AUTOSAR XML (schema 4-0-3)
standard types defined: Boolean, UInt32, UInt8
package /AUTOSAR_Platform/DataConstrs
  range DC_Boolean: raw 0..1
  range DC_UInt8: raw 0..255
package /PATAC/MSM/ComponentTypes
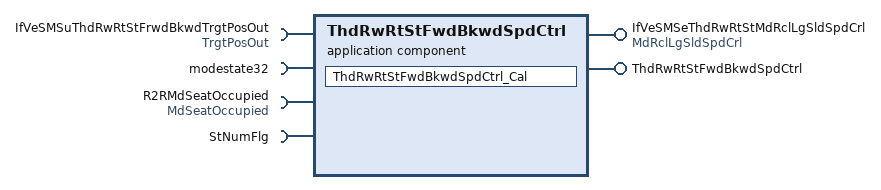
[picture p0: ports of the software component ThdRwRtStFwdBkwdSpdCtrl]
  application sw component type ThdRwRtStFwdBkwdSpdCtrl
    provide port IfVeSMSeThdRwRtStMdRclLgSldSpdCrl: nonqueued-sender-com-spec{data-element=MdRclLgSldSpdCrl/Val, init-value=0}, provided-interface=MdRclLgSldSpdCrl
    provide port ThdRwRtStFwdBkwdSpdCtrl: server-com-spec{operation=Cal, queue-length=1}, provided-interface=ThdRwRtStFwdBkwdSpdCtrl
    4 x require port:
      IfVeSMSuThdRwRtStFrwdBkwdTrgtPosOut: nonqueued-receiver-com-spec{data-element=TrgtPosOut/Val, filter=data-filter-type=ALWAYS, init-value=0}, required-interface=TrgtPosOut
      modestate32: nonqueued-receiver-com-spec{data-element=modestate32/Val, filter=data-filter-type=ALWAYS, init-value=0}, required-interface=modestate32
      R2RMdSeatOccupied: nonqueued-receiver-com-spec{data-element=MdSeatOccupied/Val, filter=data-filter-type=ALWAYS, init-value=0}, required-interface=MdSeatOccupied
      StNumFlg: required-interface=StNumFlg
        required-com-specs:
          data-element=Is4s, filter=data-filter-type=ALWAYS, init-value=0
          data-element=Is6s, filter=data-filter-type=ALWAYS, init-value=0
          data-element=Is6s7s, filter=data-filter-type=ALWAYS, init-value=0
          data-element=Is7s, filter=data-filter-type=ALWAYS, init-value=0
    behavior ThdRwRtStFwdBkwdSpdCtrl_InternalBehavior
      operation invoked event OIT_ThdRwRtStFwdBkwdSpdCtrl_Cal_ThdRwRtStFwdBkwdSpdCtrl_Cal: start-on-event=ThdRwRtStFwdBkwdSpdCtrl_Cal, operation=ThdRwRtStFwdBkwdSpdCtrl.Cal
      runnable ThdRwRtStFwdBkwdSpdCtrl_Cal
        data-receive-point-by-arguments:
          7 x access:
            REC_IfVeSMSuThdRwRtStFrwdBkwdTrgtPosOut_Val: accessed-variable=IfVeSMSuThdRwRtStFrwdBkwdTrgtPosOut.Val
            REC_modestate32_Val: accessed-variable=modestate32.Val
            REC_R2RMdSeatOccupied_Val: accessed-variable=R2RMdSeatOccupied.Val
            REC_StNumFlg_Is4s: accessed-variable=StNumFlg.Is4s
            REC_StNumFlg_Is6s: accessed-variable=StNumFlg.Is6s
            REC_StNumFlg_Is6s7s: accessed-variable=StNumFlg.Is6s7s
            REC_StNumFlg_Is7s: accessed-variable=StNumFlg.Is7s
        data-send-points:
          access SEND_IfVeSMSeThdRwRtStMdRclLgSldSpdCrl_Val: accessed-variable=IfVeSMSeThdRwRtStMdRclLgSldSpdCrl.Val
  swc implementation ThdRwRtStFwdBkwdSpdCtrl_Implementation: behavior=ThdRwRtStFwdBkwdSpdCtrl_InternalBehavior
    code-descriptors:
      code Default: artifact-descriptors=autosar-engineering-object={short-label=Default, category=SWSRC}
package /PATAC/MSM/ModeAdjust/PortInterface
  client server interface ThdRwRtStFwdBkwdSpdCtrl
    operation Cal
  5 x sender receiver interface:
    MdRclLgSldSpdCrl: invalidation-policy{data-element=MdRclLgSldSpdCrl/Val, handle-invalid=DONT-INVALIDATE}
      data Val: type=UInt8
    MdSeatOccupied: invalidation-policy{data-element=MdSeatOccupied/Val, handle-invalid=DONT-INVALIDATE}
      data Val: type=Boolean
    modestate32: invalidation-policy{data-element=modestate32/Val, handle-invalid=DONT-INVALIDATE}
      data Val: type=UInt32
    StNumFlg
      4 x data, all with type=Boolean:
        Is4s
        Is6s
        Is6s7s
        Is7s
      invalidation-policys:
        data-element=Is7s, handle-invalid=DONT-INVALIDATE
        data-element=Is6s, handle-invalid=DONT-INVALIDATE
        data-element=Is4s, handle-invalid=DONT-INVALIDATE
        data-element=Is6s7s, handle-invalid=DONT-INVALIDATE
    TrgtPosOut: invalidation-policy{data-element=TrgtPosOut/Val, handle-invalid=DONT-INVALIDATE}
      data Val: type=Boolean
